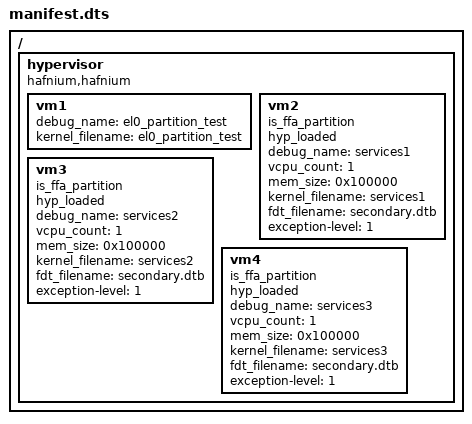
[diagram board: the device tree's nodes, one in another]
/*
 * Copyright 2021 The Hafnium Authors.
 *
 * Use of this source code is governed by a BSD-style
 * license that can be found in the LICENSE file or at
 * https://opensource.org/licenses/BSD-3-Clause.
 */

/dts-v1/;

/ {
	hypervisor {
		compatible = "hafnium,hafnium";
		vm1 {
			debug_name = "el0_partition_test";
			kernel_filename = "el0_partition_test";
		};

		vm2 {
			is_ffa_partition;
			hyp_loaded;
			debug_name = "services1";
			vcpu_count = <1>;
			mem_size = <0x100000>;
			kernel_filename = "services1";
			fdt_filename = "secondary.dtb";
			exception-level = <1>;
		};

		vm3 {
			is_ffa_partition;
			hyp_loaded;
			debug_name = "services2";
			vcpu_count = <1>;
			mem_size = <0x100000>;
			kernel_filename = "services2";
			fdt_filename = "secondary.dtb";
			exception-level = <1>;
		};

		vm4 {
			is_ffa_partition;
			hyp_loaded;
			debug_name = "services3";
			vcpu_count = <1>;
			mem_size = <0x100000>;
			kernel_filename = "services3";
			fdt_filename = "secondary.dtb";
			exception-level = <1>;
		};
	};
};
